# R7FA6M4AF register map
Vendor: Renesas Electronics Corporation; Series: RA6; File version: 1.20.04
CPU: CM33 r0p4, little endian, MPU, FPU, VTOR, 4 interrupt priority bits, 96 interrupts
Registers are 8-bit, read-write, reset 0x0 unless marked. A register's access mark holds for its fields unless they carry their own. Offsets are from the block's base; [hi:lo] are bit positions.

## SSIE0 — Serial Sound Interface Enhanced (SSIE)
Base 0x4009D000
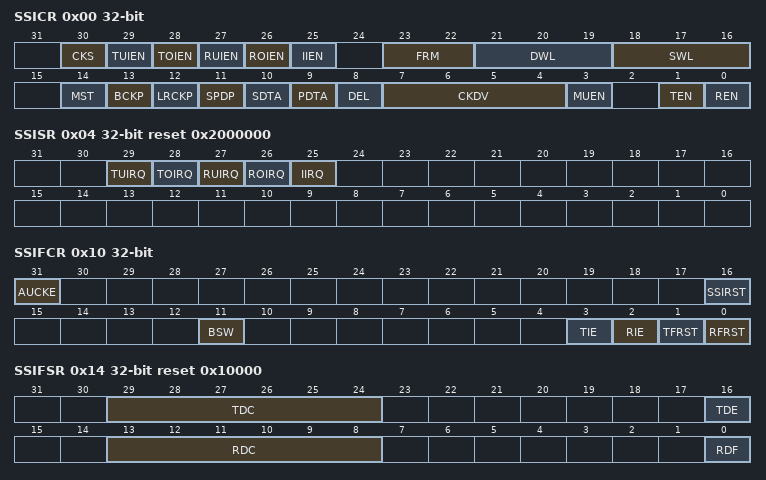
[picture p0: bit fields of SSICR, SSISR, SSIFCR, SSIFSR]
0x00 SSICR 32-bit — Control Register
  [30] CKS — Selects an Audio Clock for Master-mode Communication
    0=Selects the AUDIO_CLK input; 1=Selects the GTIOC2A (GPT output)
  [29] TUIEN — Transmit Underflow Interrupt Output Enable
    0=Disables transmit underflow interrupt output; 1=Enables transmit underflow interrupt output
  [28] TOIEN — Transmit Overflow Interrupt Output Enable
    0=Disables transmit overflow interrupt output; 1=Enables transmit overflow interrupt output
  [27] RUIEN — Receive Underflow Interrupt Output Enable
    0=Disables receive underflow interrupt output; 1=Enables receive underflow interrupt output
  [26] ROIEN — Receive Overflow Interrupt Output Enable
    0=Disables receive overflow interrupt output; 1=Enables receive overflow interrupt output
  [25] IIEN — Idle Mode Interrupt Output Enable
    0=Disables idle mode interrupt output; 1=Enables idle mode interrupt output
  [23:22] FRM — Selects Frame Word Number
  [21:19] DWL — Selects Data Word Length
    0=8 bits; 1=16 bits; 2=18 bits; 3=20 bits; 4=22 bits; 5=24 bits; 6=32 bits; 7=Setting prohibited
  [18:16] SWL — Selects System Word Length
    0=8 bits; 1=16 bits; 2=24 bits; 3=32 bits; 4=48 bits; 5=64 bits; 6=128 bits; 7=256 bits
  [14] MST — Master Enable
    0=Slave-mode communication; 1=Master-mode communication
  [13] BCKP — Selects Bit Clock Polarity
    0=SSILRCK/SSIFS and SSITXD0/SSIRXD0/SSIDATA0 change at a falling edge (SSILRCK/SSIFS and SSIRXD0/SSIDATA0 are sampled at a rising edge of SSIBCK); 1=SSILRCK/SSIFS and SSITXD0/SSIRXD0/SSIDATA0 change at a rising edge (SSILRCK/SSIFS and SSIRXD0/SSIDATA0 are sampled at a falling edge of SSIBCK)
  [12] LRCKP — Selects the Initial Value and Polarity of LR Clock/Frame Synchronization Signal
    0=The initial value is at a high level. The start trigger for a frame is synchronized with a falling edge of SSILRCK/SSIFS.; 1=The initial value is at a low level. The start trigger for a frame is synchronized with a rising edge of SSILRCK/SSIFS.
  [11] SPDP — Selects Serial Padding Polarity
    0=Padding data is at a low level; 1=Padding data is at a high level
  [10] SDTA — Selects Serial Data Alignment
    0=Transmits and receives serial data first and then padding bits; 1=Transmit and receives padding bits first and then serial data
  [9] PDTA — Selects Placement Data Alignment
    0=Left-justifies placement data (SSIFTDR, SSIFRDR); 1=Right-justifies placement data (SSIFTDR, SSIFRDR)
  [8] DEL — Selects Serial Data Delay
    0=Delay of 1 cycle of SSIBCK between SSILRCK/SSIFS and SSITXD0/SSIRXD0/SSIDATA0; 1=No delay between SSILRCK/SSIFS and SSITXD0/SSIRXD0/SSIDATA0
  [7:4] CKDV — Selects Bit Clock Division Ratio
    0=AUDIO_MCK; 1=AUDIO_MCK/2; 2=AUDIO_MCK/4; 3=AUDIO_MCK/8; 4=AUDIO_MCK/16; 5=AUDIO_MCK/32; 6=AUDIO_MCK/64; 7=AUDIO_MCK/128; 8=AUDIO_MCK/6; 9=AUDIO_MCK/12; 10=AUDIO_MCK/24; 11=AUDIO_MCK/48; 12=AUDIO_MCK/96; other=Others (Setting prohibited)
  [3] MUEN — Mute Enable
    0=Disables muting on the next frame boundary; 1=Enables muting on the next frame boundary
  [1] TEN — Transmission Enable
    0=Disables transmission; 1=Enables transmission (starts transmission)
  [0] REN — Reception Enable
    0=Disables reception; 1=Enables reception (starts reception)
0x04 SSISR 32-bit reset 0x2000000 — Status Register
  [29] TUIRQ — Transmit Underflow Error Status flag
    0=No transmit underflow error is generated; 1=A transmit underflow error is generated
  [28] TOIRQ — Transmit Overflow Error Status Flag
    0=No transmit overflow error is generated; 1=A transmit overflow error is generated
  [27] RUIRQ — Receive Underflow Error Status Flag
    0=No receive underflow error is generated; 1=A receive underflow error is generated
  [26] ROIRQ — Receive Overflow Error Status Flag
    0=No receive overflow error is generated; 1=A receive overflow error is generated
  [25] IIRQ ro — Idle Mode Status Flag
    0=In the communication state; 1=In the idle state
0x10 SSIFCR 32-bit — FIFO Control Register
  [31] AUCKE — AUDIO_MCK Enable in Mastermode Communication
    0=Disables supply of AUDIO_MCK; 1=Enables supply of AUDIO_MCK
  [16] SSIRST — Software Reset
    0=Clears a software reset condition; 1=Sets a software reset condition
  [11] BSW — Byte Swap Enable
    0=Disables byte swap; 1=Enables byte swap
  [3] TIE — Transmit Data Empty Interrupt Output Enable
    0=Disables transmit data empty interrupts; 1=Enables transmit data empty interrupts
  [2] RIE — Receive Data Full Interrupt Output Enable
    0=Disables receive data full interrupts; 1=Enables receive data full interrupts
  [1] TFRST — Transmit FIFO Data Register Reset
    0=Clears a transmit data FIFO reset condition; 1=Sets a transmit data FIFO reset condition
  [0] RFRST — Receive FIFO Data Register Reset
    0=Clears a receive data FIFO reset condition; 1=Sets a receive data FIFO reset condition
0x14 SSIFSR 32-bit reset 0x10000 — FIFO Status Register
  [29:24] TDC ro — Number of Transmit FIFO Data Indication Flag
  [16] TDE — Transmit Data Empty Flag
    0=The free space of SSIFTDR is not more than the value of SSISCR.TDES; 1=The free space of SSIFTDR is not less than the value of SSISCR.TDES plus one
  [13:8] RDC ro — Number of Receive FIFO Data Indication Flag
  [0] RDF — Receive Data Full Flag
    0=The size of received data in SSIFRDR is not more than the value of SSISCR.RDFS; 1=The size of received data in SSIFRDR is not less than the value of SSISCR.RDFS plus one
0x18 SSIFTDR 32-bit wo — Transmit FIFO Data Register
  [31:0] SSIFTDR — Transmit FIFO Data
0x1C SSIFRDR 32-bit ro — Receive FIFO Data Register
  [31:0] SSIFRDR — Receive FIFO Data
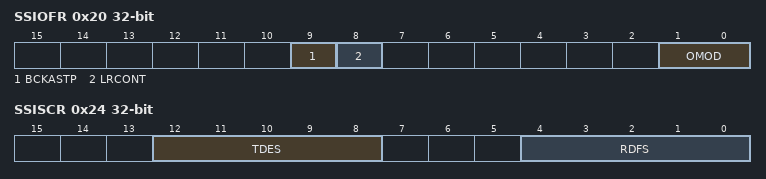
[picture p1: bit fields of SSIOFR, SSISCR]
0x20 SSIOFR 32-bit — Audio Format Register
  [9] BCKASTP — Whether to Enable Stopping BCK Output When SSIE is in Idle Status
    0=Always outputs BCK to the SSIBCK pin; 1=Automatically controls output of BCK to the SSIBCK pin
  [8] LRCONT — Whether to Enable LRCK/FS Continuation
    0=Disables LRCK/FS continuation; 1=Enables LRCK/FS continuation
  [1:0] OMOD — Audio Format Select
    0=I2S format; 1=TDM format; 2=Monaural format; 3=Setting prohibited
0x24 SSISCR 32-bit — Status Control Register
  [12:8] TDES — TDE Setting Condition Select
  [4:0] RDFS — RDF Setting Condition Select
